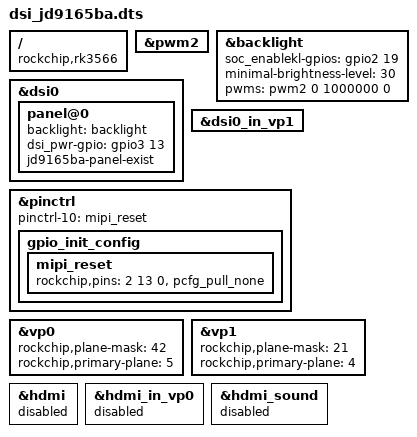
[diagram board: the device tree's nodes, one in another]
/dts-v1/;
/plugin/;
/ {
        compatible = "rockchip,rk3566";

        fragment@0 {
                target = <&pwm2>;
                __overlay__ {
                        status = "okay";
                };
        };
        fragment@1 {
                target = <&backlight>;
                __overlay__ {
                        status = "okay";
                        soc_enablekl-gpios = <&gpio2 19 0>;
                        minimal-brightness-level = <30>;
			pwms = <&pwm2 0 1000000 0>;
                };
        };
        fragment@2 {
                target = <&dsi0>;
                __overlay__ {
                        status = "okay";
                        panel@0 {
                                backlight = <&backlight>;
				dsi_pwr-gpio = <&gpio3 13 0>;
                                jd9165ba-panel-exist;
                        };
                };
        };
        fragment@3 {
                target = <&dsi0_in_vp1>;
                __overlay__ {
                        status = "okay";
                };
        };
        fragment@4 {
                target = <&pinctrl>;
                __overlay__ {
                        pinctrl-10 = <&mipi_reset>;
                        gpio_init_config {
                                mipi_reset: mipi_reset {
                                        rockchip,pins =
                                                <2 13 0 &pcfg_pull_none>;
                                };
                        };
                };
        };
        fragment@5 {
                target = <&vp0>;
                __overlay__ {
			rockchip,plane-mask = <42>; //rockchip,plane-mask = <(1 << ROCKCHIP_VOP2_CLUSTER1 | 1 << ROCKCHIP_VOP2_SMART1 | 1 << ROCKCHIP_VOP2_ESMART1)>;
			rockchip,primary-plane = <5>; ///*rockchip,primary-plane = <ROCKCHIP_VOP2_SMART1>;*/
                };
        };
        fragment@6 {
                target = <&vp1>;
                __overlay__ {
			rockchip,plane-mask = <21>; //rockchip,plane-mask = <(1 << ROCKCHIP_VOP2_CLUSTER0 | 1 << ROCKCHIP_VOP2_SMART0 | 1 << ROCKCHIP_VOP2_ESMART0)>;
			rockchip,primary-plane = <4>; ///*rockchip,primary-plane = <ROCKCHIP_VOP2_SMART0>;*/
                };
        };
	fragment@7{
		target = <&hdmi>;
                __overlay__ {
                        status = "disabled";
		};
	};
	fragment@8{
		target = <&hdmi_in_vp0>;
                __overlay__ {
                        status = "disabled";
		};
	};
	fragment@9{
		target = <&hdmi_sound>;
                __overlay__ {
                        status = "disabled";
		};
	};
};
